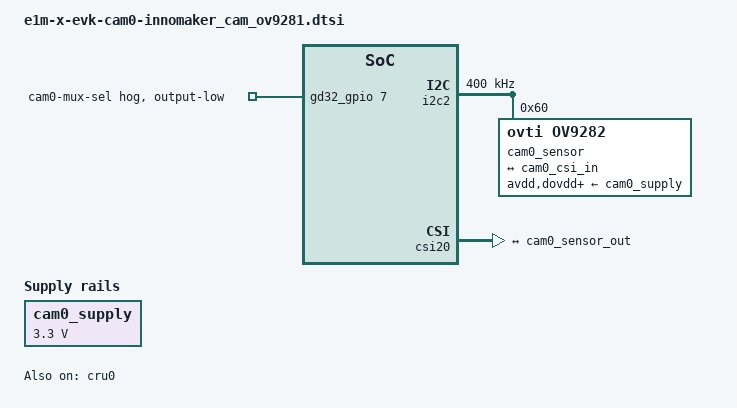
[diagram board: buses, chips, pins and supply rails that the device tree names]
// SPDX-License-Identifier: (GPL-2.0-only OR BSD-2-Clause)
/*
 * GENERATED by scripts/gen_camera_dt.py -- DO NOT EDIT BY HAND.
 * InnoMaker CAM-OV9281 (OV9281 global-shutter mono, 2-lane CSI-2) on the e1m-x-evk CAM0 connector (J5) ->
 * RZ/V2N MIPI CSI-2 receiver (csi20) -> cru0 -> /dev/video*.
 *
 * Inputs: metadata/camera_modules/innomaker_cam_ov9281.yaml, metadata/chips/ov9281.yaml,
 * metadata/boards/e1m-x-evk.yaml camera_connectors.CAM0, the E1M-V2N/V2M pad_routes,
 * metadata/socs/renesas/rzv2n/n44.json linux_dt.
 *
 * NOT part of the default dtb: the linux-renesas bbappend builds it into the
 * cam0 dtb when ALP_CAMERA_CAM0 = "innomaker_cam_ov9281".
 * Link frequency, lanes, supplies and clock follow the ovti,ov9282 driver
 * facts in metadata/chips/ov9281.yaml (drivers.linux).
 *
 * GD32 bridge lines (line number = index in &gd32_gpio gpio-line-names):
 * XEVK_PIN_CAM0_MUX_SEL = E1M IO16 = GD32 PC0, bridge line 7
 *
 * Not modelled:
 *   - XEVK_PIN_CAM0_EN (E1M_X_GPIO_IO18): SoM route is TBD; the camera enable is not driven from Linux
 *   - XEVK_PIN_CAM0_RST (E1M_X_GPIO_IO20): SoM route is TBD; the camera reset is not driven from Linux
 */

/ {
	cam0_xclk: cam0-xclk {
		compatible = "fixed-clock";
		#clock-cells = <0>;
		clock-frequency = <24000000>;
	};

	cam0_supply: regulator-cam0-3v3 {
		compatible = "regulator-fixed";
		regulator-name = "cam0-3v3";
		regulator-min-microvolt = <3300000>;
		regulator-max-microvolt = <3300000>;
		regulator-always-on;
	};

	aliases {
		alp-camera0 = &cam0_sensor;
	};
};

&gd32_gpio {
	cam0-mux-sel-hog {
		gpio-hog;
		gpios = <7 GPIO_ACTIVE_HIGH>;
		output-low;
		line-name = "cam0-mux-sel";
	};
};

&pinctrl {
	/* E1M_X_I2C2 (XEVK_I2C_BUS_DSI_CSI0) = i2c2 */
	i2c2_pins: i2c2 {
		pinmux = <RZV2N_PORT_PINMUX(3, 4, 1)>, /* I2C2_SDA */
			 <RZV2N_PORT_PINMUX(3, 5, 1)>; /* I2C2_SCL */
	};
};

&i2c2 {
	pinctrl-0 = <&i2c2_pins>;
	pinctrl-names = "default";
	clock-frequency = <400000>;
	status = "okay";

	cam0_sensor: camera@60 {
		compatible = "ovti,ov9282";
		reg = <0x60>;
		clocks = <&cam0_xclk>;
		avdd-supply = <&cam0_supply>;
		dovdd-supply = <&cam0_supply>;
		dvdd-supply = <&cam0_supply>;

		port {
			cam0_sensor_out: endpoint {
				remote-endpoint = <&cam0_csi_in>;
				data-lanes = <1 2>;
				link-frequencies = /bits/ 64 <400000000>;
				clock-noncontinuous;
			};
		};
	};
};

&csi20 {
	status = "okay";

	ports {
		#address-cells = <1>;
		#size-cells = <0>;

		port@0 {
			reg = <0>;
			cam0_csi_in: endpoint {
				remote-endpoint = <&cam0_sensor_out>;
				data-lanes = <1 2>;
				/* clock + data lanes; the connector's `lane_polarity` (rzg2l-csi2 patch 0017). */
				lane-polarities = <1 1 1>;
			};
		};
	};
};

&cru0 {
	status = "okay";
};
